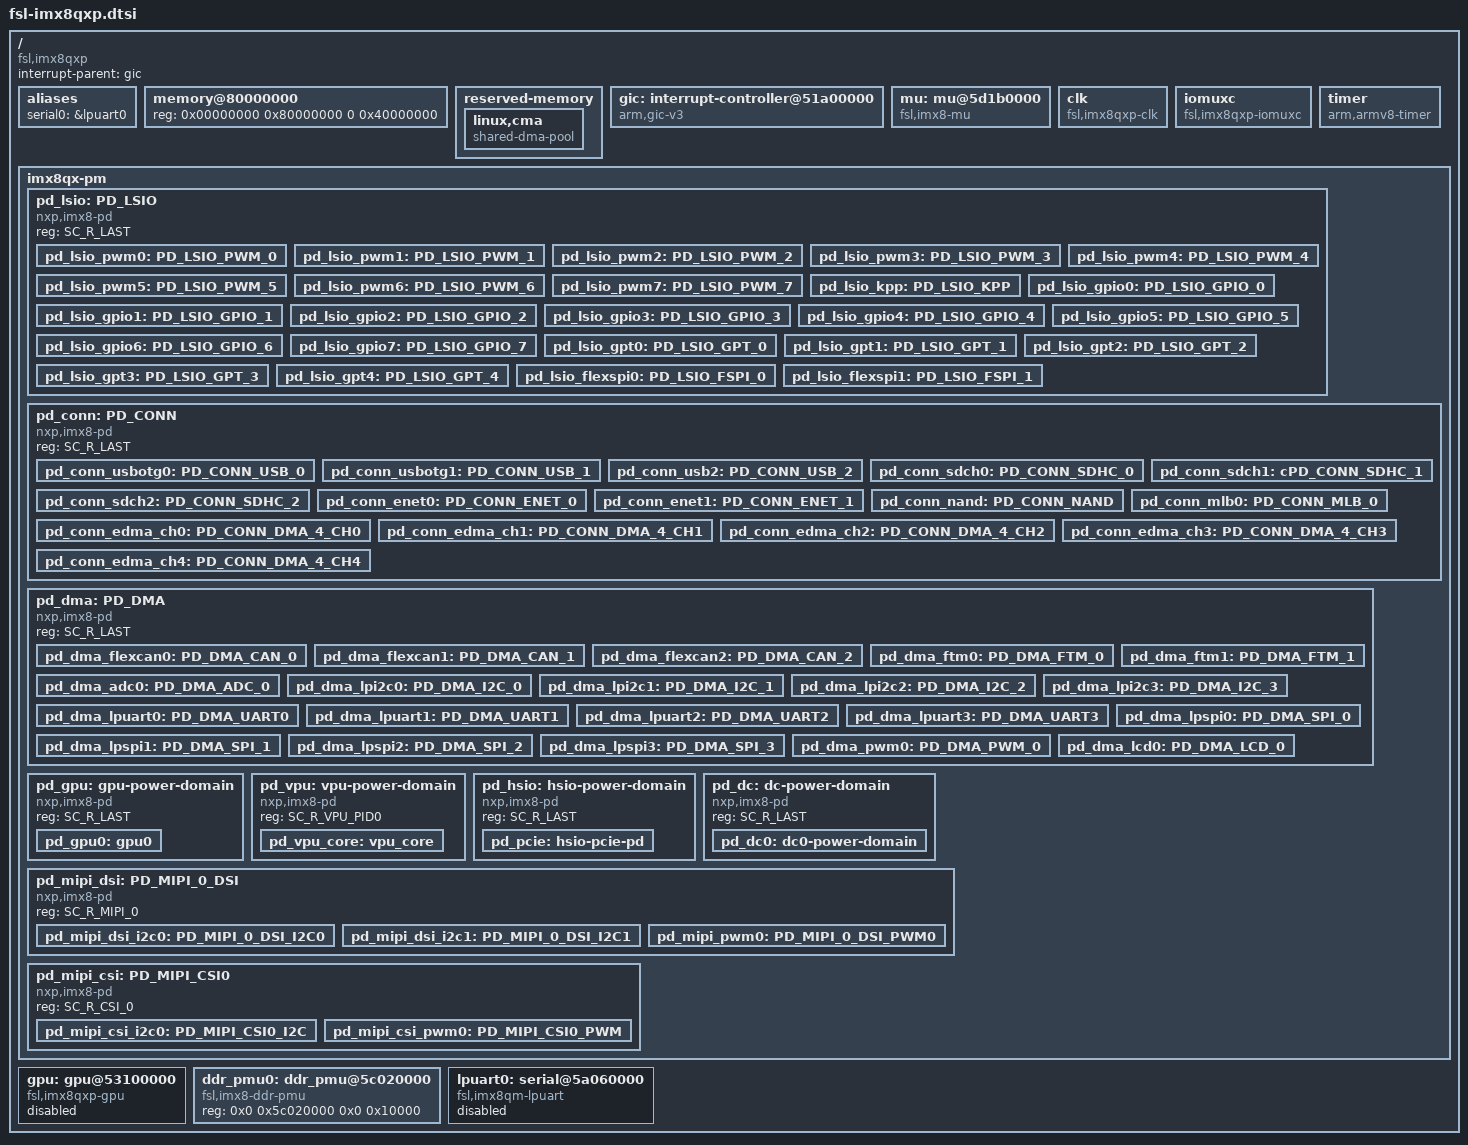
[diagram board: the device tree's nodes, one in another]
/*
 * Copyright (C) 2016 Freescale Semiconductor, Inc.
 * Copyright 2017 NXP
 *
 * This program is free software; you can redistribute it and/or
 * modify it under the terms of the GNU General Public License
 * as published by the Free Software Foundation; either version 2
 * of the License, or (at your option) any later version.
 *
 * This program is distributed in the hope that it will be useful,
 * but WITHOUT ANY WARRANTY; without even the implied warranty of
 * MERCHANTABILITY or FITNESS FOR A PARTICULAR PURPOSE.  See the
 * GNU General Public License for more details.
 */

#include <dt-bindings/interrupt-controller/arm-gic.h>
#include "fsl-imx8-ca35.dtsi"
#include <dt-bindings/soc/imx_rsrc.h>
#include <dt-bindings/soc/imx8_pd.h>
#include <dt-bindings/clock/imx8qxp-clock.h>
#include <dt-bindings/pinctrl/pads-imx8qxp.h>

/ {
	compatible = "fsl,imx8qxp";
	interrupt-parent = <&gic>;
	#address-cells = <2>;
	#size-cells = <2>;

	aliases {
		serial0 = &lpuart0;
	};

	memory@80000000 {
		device_type = "memory";
		reg = <0x00000000 0x80000000 0 0x40000000>;
		      /* DRAM space - 1, size : 1 GB DRAM */
	};

	reserved-memory {
		#address-cells = <2>;
		#size-cells = <2>;
		ranges;

		/* global autoconfigured region for contiguous allocations */
		linux,cma {
			compatible = "shared-dma-pool";
			reusable;
			size = <0 0x08000000>;
			alloc-ranges = <0 0x80000000 0 0x80000000>;
			linux,cma-default;
		};
	};

	gic: interrupt-controller@51a00000 {
		compatible = "arm,gic-v3";
		reg = <0x0 0x51a00000 0 0x10000>, /* GIC Dist */
		      <0x0 0x51b00000 0 0xC0000>; /* GICR (RD_base + SGI_base) */
		#interrupt-cells = <3>;
		interrupt-controller;
		interrupts = <GIC_PPI 9
			(GIC_CPU_MASK_SIMPLE(6) | IRQ_TYPE_LEVEL_HIGH)>;
	};

	mu: mu@5d1b0000 {
		compatible = "fsl,imx8-mu";
		reg = <0x0 0x5d1b0000 0x0 0x10000>;
		interrupts = <GIC_SPI 176 IRQ_TYPE_LEVEL_HIGH>;
		fsl,scu_ap_mu_id = <0>;
		status = "okay";
	};

	clk: clk {
		compatible = "fsl,imx8qxp-clk";
		#clock-cells = <1>;
	};

	iomuxc: iomuxc {
		compatible = "fsl,imx8qxp-iomuxc";
	};

	timer {
		compatible = "arm,armv8-timer";
		interrupts = <GIC_PPI 13 (GIC_CPU_MASK_SIMPLE(6) | IRQ_TYPE_LEVEL_LOW)>, /* Physical Secure */
			     <GIC_PPI 14 (GIC_CPU_MASK_SIMPLE(6) | IRQ_TYPE_LEVEL_LOW)>, /* Physical Non-Secure */
			     <GIC_PPI 11 (GIC_CPU_MASK_SIMPLE(6) | IRQ_TYPE_LEVEL_LOW)>, /* Virtual */
			     <GIC_PPI 10 (GIC_CPU_MASK_SIMPLE(6) | IRQ_TYPE_LEVEL_LOW)>; /* Hypervisor */
		clock-frequency = <8000000>;
	};

	imx8qx-pm {
		#address-cells = <1>;
		#size-cells = <0>;

		pd_lsio: PD_LSIO {
			compatible = "nxp,imx8-pd";
			reg = <SC_R_LAST>;
			#power-domain-cells = <0>;
			#address-cells = <1>;
			#size-cells = <0>;

			pd_lsio_pwm0: PD_LSIO_PWM_0 {
				reg = <SC_R_PWM_0>;
				#power-domain-cells = <0>;
				power-domains = <&pd_lsio>;
			};
			pd_lsio_pwm1: PD_LSIO_PWM_1 {
				reg = <SC_R_PWM_1>;
				#power-domain-cells = <0>;
				power-domains = <&pd_lsio>;
			};
			pd_lsio_pwm2: PD_LSIO_PWM_2 {
				reg = <SC_R_PWM_2>;
				#power-domain-cells = <0>;
				power-domains = <&pd_lsio>;
			};
			pd_lsio_pwm3: PD_LSIO_PWM_3 {
				reg = <SC_R_PWM_3>;
				#power-domain-cells = <0>;
				power-domains = <&pd_lsio>;
			};
			pd_lsio_pwm4: PD_LSIO_PWM_4 {
				reg = <SC_R_PWM_4>;
				#power-domain-cells = <0>;
				power-domains = <&pd_lsio>;
			};
			pd_lsio_pwm5: PD_LSIO_PWM_5 {
				reg = <SC_R_PWM_5>;
				#power-domain-cells = <0>;
				power-domains = <&pd_lsio>;
			};
			pd_lsio_pwm6: PD_LSIO_PWM_6 {
				reg = <SC_R_PWM_6>;
				#power-domain-cells = <0>;
				power-domains = <&pd_lsio>;
			};
			pd_lsio_pwm7: PD_LSIO_PWM_7 {
				reg = <SC_R_PWM_7>;
				#power-domain-cells = <0>;
				power-domains = <&pd_lsio>;
			};
			pd_lsio_kpp: PD_LSIO_KPP {
				reg = <SC_R_KPP>;
				#power-domain-cells = <0>;
				power-domains = <&pd_lsio>;
			};
			pd_lsio_gpio0: PD_LSIO_GPIO_0 {
				reg = <SC_R_GPIO_0>;
				#power-domain-cells = <0>;
				power-domains = <&pd_lsio>;
			};
			pd_lsio_gpio1: PD_LSIO_GPIO_1 {
				reg = <SC_R_GPIO_1>;
				#power-domain-cells = <0>;
				power-domains = <&pd_lsio>;
			};
			pd_lsio_gpio2: PD_LSIO_GPIO_2 {
				reg = <SC_R_GPIO_2>;
				#power-domain-cells = <0>;
				power-domains = <&pd_lsio>;
			};
			pd_lsio_gpio3: PD_LSIO_GPIO_3 {
				reg = <SC_R_GPIO_3>;
				#power-domain-cells = <0>;
				power-domains = <&pd_lsio>;
			};
			pd_lsio_gpio4: PD_LSIO_GPIO_4 {
				reg = <SC_R_GPIO_4>;
				#power-domain-cells = <0>;
				power-domains = <&pd_lsio>;
			};
			pd_lsio_gpio5: PD_LSIO_GPIO_5{
				reg = <SC_R_GPIO_5>;
				#power-domain-cells = <0>;
				power-domains = <&pd_lsio>;
			};
			pd_lsio_gpio6:PD_LSIO_GPIO_6 {
				reg = <SC_R_GPIO_6>;
				#power-domain-cells = <0>;
				power-domains = <&pd_lsio>;
			};
			pd_lsio_gpio7: PD_LSIO_GPIO_7 {
				reg = <SC_R_GPIO_7>;
				#power-domain-cells = <0>;
				power-domains = <&pd_lsio>;
			};
			pd_lsio_gpt0: PD_LSIO_GPT_0 {
				reg = <SC_R_GPT_0>;
				#power-domain-cells = <0>;
				power-domains = <&pd_lsio>;
			};
			pd_lsio_gpt1: PD_LSIO_GPT_1 {
				reg = <SC_R_GPT_1>;
				#power-domain-cells = <0>;
				power-domains = <&pd_lsio>;
			};
			pd_lsio_gpt2: PD_LSIO_GPT_2 {
				reg = <SC_R_GPT_2>;
				#power-domain-cells = <0>;
				power-domains = <&pd_lsio>;
			};
			pd_lsio_gpt3: PD_LSIO_GPT_3 {
				reg = <SC_R_GPT_3>;
				#power-domain-cells = <0>;
				power-domains = <&pd_lsio>;
			};
			pd_lsio_gpt4: PD_LSIO_GPT_4 {
				reg = <SC_R_GPT_4>;
				#power-domain-cells = <0>;
				power-domains = <&pd_lsio>;
			};
			pd_lsio_flexspi0: PD_LSIO_FSPI_0 {
				reg = <SC_R_FSPI_0>;
				#power-domain-cells = <0>;
				power-domains = <&pd_lsio>;
			};
			pd_lsio_flexspi1: PD_LSIO_FSPI_1{
				reg = <SC_R_FSPI_1>;
				#power-domain-cells = <0>;
				power-domains = <&pd_lsio>;
			};
		};

		pd_conn: PD_CONN {
			compatible = "nxp,imx8-pd";
			reg = <SC_R_LAST>;
			#power-domain-cells = <0>;
			#address-cells = <1>;
			#size-cells = <0>;

			pd_conn_usbotg0: PD_CONN_USB_0 {
				reg = <SC_R_USB_0>;
				#power-domain-cells = <0>;
				power-domains = <&pd_conn>;
			};
			pd_conn_usbotg1: PD_CONN_USB_1 {
				reg = <SC_R_USB_1>;
				#power-domain-cells = <0>;
				power-domains = <&pd_conn>;
			};
			pd_conn_usb2: PD_CONN_USB_2 {
				reg = <SC_R_USB_2>;
				#power-domain-cells = <0>;
				power-domains = <&pd_conn>;
			};
			pd_conn_sdch0: PD_CONN_SDHC_0 {
				reg = <SC_R_SDHC_0>;
				#power-domain-cells = <0>;
				power-domains = <&pd_conn>;
			};
			pd_conn_sdch1: cPD_CONN_SDHC_1 {
				reg = <SC_R_SDHC_1>;
				#power-domain-cells = <0>;
				power-domains = <&pd_conn>;
			};
			pd_conn_sdch2: PD_CONN_SDHC_2 {
				reg = <SC_R_SDHC_2>;
				#power-domain-cells = <0>;
				power-domains = <&pd_conn>;
			};
			pd_conn_enet0: PD_CONN_ENET_0 {
				reg = <SC_R_ENET_0>;
				#power-domain-cells = <0>;
				power-domains = <&pd_conn>;
			};
			pd_conn_enet1: PD_CONN_ENET_1 {
				reg = <SC_R_ENET_1>;
				#power-domain-cells = <0>;
				power-domains = <&pd_conn>;
			};
			pd_conn_nand: PD_CONN_NAND {
				reg = <SC_R_NAND>;
				#power-domain-cells = <0>;
				power-domains = <&pd_conn>;
			};
			pd_conn_mlb0: PD_CONN_MLB_0 {
				reg = <SC_R_MLB_0>;
				#power-domain-cells = <0>;
				power-domains = <&pd_conn>;
			};
			pd_conn_edma_ch0: PD_CONN_DMA_4_CH0 {
				reg = <SC_R_DMA_4_CH0>;
				#power-domain-cells = <0>;
				power-domains =<&pd_conn>;
			};
			pd_conn_edma_ch1: PD_CONN_DMA_4_CH1 {
				reg = <SC_R_DMA_4_CH1>;
				#power-domain-cells = <0>;
				power-domains =<&pd_conn>;
			};
			pd_conn_edma_ch2: PD_CONN_DMA_4_CH2 {
				reg = <SC_R_DMA_4_CH2>;
				#power-domain-cells = <0>;
				power-domains =<&pd_conn>;
			};
			pd_conn_edma_ch3: PD_CONN_DMA_4_CH3 {
				reg = <SC_R_DMA_4_CH3>;
				#power-domain-cells = <0>;
				power-domains =<&pd_conn>;
			};
			pd_conn_edma_ch4: PD_CONN_DMA_4_CH4 {
				reg = <SC_R_DMA_4_CH4>;
				#power-domain-cells = <0>;
				power-domains =<&pd_conn>;
			};
		};

		pd_dma: PD_DMA {
			compatible = "nxp,imx8-pd";
			reg = <SC_R_LAST>;
			#power-domain-cells = <0>;
			#address-cells = <1>;
			#size-cells = <0>;

			pd_dma_flexcan0: PD_DMA_CAN_0 {
				reg = <SC_R_CAN_0>;
				#power-domain-cells = <0>;
				power-domains = <&pd_dma>;
			};
			pd_dma_flexcan1: PD_DMA_CAN_1 {
				reg = <SC_R_CAN_1>;
				#power-domain-cells = <0>;
				power-domains = <&pd_dma>;
			};
			pd_dma_flexcan2: PD_DMA_CAN_2 {
				reg = <SC_R_CAN_2>;
				#power-domain-cells = <0>;
				power-domains = <&pd_dma>;
			};
			pd_dma_ftm0: PD_DMA_FTM_0 {
				reg = <SC_R_FTM_0>;
				#power-domain-cells = <0>;
				power-domains = <&pd_dma>;
			};
			pd_dma_ftm1: PD_DMA_FTM_1 {
				reg = <SC_R_FTM_1>;
				#power-domain-cells = <0>;
				power-domains = <&pd_dma>;
			};
			pd_dma_adc0: PD_DMA_ADC_0 {
				reg = <SC_R_ADC_0>;
				#power-domain-cells = <0>;
				power-domains = <&pd_dma>;
			};
			pd_dma_lpi2c0: PD_DMA_I2C_0 {
				reg = <SC_R_I2C_0>;
				#power-domain-cells = <0>;
				power-domains = <&pd_dma>;
			};
			pd_dma_lpi2c1: PD_DMA_I2C_1 {
				reg = <SC_R_I2C_1>;
				#power-domain-cells = <0>;
				power-domains = <&pd_dma>;
			};
			pd_dma_lpi2c2:PD_DMA_I2C_2 {
				reg = <SC_R_I2C_2>;
				#power-domain-cells = <0>;
				power-domains = <&pd_dma>;
			};
			pd_dma_lpi2c3: PD_DMA_I2C_3 {
				reg = <SC_R_I2C_3>;
				#power-domain-cells = <0>;
				power-domains = <&pd_dma>;
			};
			pd_dma_lpuart0: PD_DMA_UART0 {
				reg = <SC_R_UART_0>;
				#power-domain-cells = <0>;
				power-domains = <&pd_dma>;
			};
			pd_dma_lpuart1: PD_DMA_UART1 {
				reg = <SC_R_UART_1>;
				#power-domain-cells = <0>;
				power-domains = <&pd_dma>;
			};
			pd_dma_lpuart2: PD_DMA_UART2 {
				reg = <SC_R_UART_2>;
				#power-domain-cells = <0>;
				power-domains = <&pd_dma>;
			};
			pd_dma_lpuart3: PD_DMA_UART3 {
				reg = <SC_R_UART_3>;
				#power-domain-cells = <0>;
				power-domains = <&pd_dma>;
			};
			pd_dma_lpspi0: PD_DMA_SPI_0 {
				reg = <SC_R_SPI_0>;
				#power-domain-cells = <0>;
				power-domains = <&pd_dma>;
			};
			pd_dma_lpspi1: PD_DMA_SPI_1 {
				reg = <SC_R_SPI_1>;
				#power-domain-cells = <0>;
				power-domains = <&pd_dma>;
			};
			pd_dma_lpspi2: PD_DMA_SPI_2 {
				reg = <SC_R_SPI_2>;
				#power-domain-cells = <0>;
				power-domains = <&pd_dma>;
			};
			pd_dma_lpspi3: PD_DMA_SPI_3 {
				reg = <SC_R_SPI_3>;
				#power-domain-cells = <0>;
				power-domains = <&pd_dma>;
			};
			pd_dma_pwm0: PD_DMA_PWM_0 {
				reg = <SC_R_LCD_0_PWM_0>;
				#power-domain-cells = <0>;
				power-domains = <&pd_dma>;
			};
			pd_dma_lcd0: PD_DMA_LCD_0 {
				reg = <SC_R_LCD_0>;
				#power-domain-cells = <0>;
				power-domains = <&pd_dma>;
			};
		};

		pd_gpu: gpu-power-domain {
			compatible = "nxp,imx8-pd";
			reg = <SC_R_LAST>;
			#power-domain-cells = <0>;
			#address-cells = <1>;
			#size-cells = <0>;

			pd_gpu0: gpu0 {
				name = "gpu0";
				reg = <SC_R_GPU_0_PID0>;
				#power-domain-cells = <0>;
				power-domains =<&pd_gpu>;
				#address-cells = <1>;
				#size-cells = <0>;
			};
		};

		pd_vpu: vpu-power-domain {
			compatible = "nxp,imx8-pd";
			reg = <SC_R_VPU_PID0>;
			#power-domain-cells = <0>;
			#address-cells = <1>;
			#size-cells = <0>;

			pd_vpu_core: vpu_core {
				name = "vpu_core";
				reg = <SC_R_VPUCORE>;
				#power-domain-cells = <0>;
				power-domains =<&pd_vpu>;
			};
		};

		pd_hsio: hsio-power-domain {
			compatible = "nxp,imx8-pd";
			reg = <SC_R_LAST>;
			#power-domain-cells = <0>;
			#address-cells = <1>;
			#size-cells = <0>;

			pd_pcie: hsio-pcie-pd {
				name = "hsio-pcie-pd";
				reg = <SC_R_PCIE_A>;
				#power-domain-cells = <0>;
				power-domains =<&pd_hsio>;
			};
		};

		pd_dc: dc-power-domain {
			compatible = "nxp,imx8-pd";
			reg = <SC_R_LAST>;
			#power-domain-cells = <0>;
			#address-cells = <1>;
			#size-cells = <0>;

			pd_dc0: dc0-power-domain {
				name = "dc0-power-domain";
				reg = <SC_R_DC_0>;
				#power-domain-cells = <0>;
				power-domains =<&pd_dc>;
			};
		};

		pd_mipi_dsi: PD_MIPI_0_DSI {
			compatible = "nxp,imx8-pd";
			reg = <SC_R_MIPI_0>;
			#power-domain-cells = <0>;
			#address-cells = <1>;
			#size-cells = <0>;

			pd_mipi_dsi_i2c0: PD_MIPI_0_DSI_I2C0 {
				name = "mipi0_dsi_i2c0";
				reg = <SC_R_MIPI_0_I2C_0>;
				power-domains =<&pd_mipi_dsi>;
			};
			pd_mipi_dsi_i2c1: PD_MIPI_0_DSI_I2C1 {
				name = "mipi0_dsi_i2c1";
				reg = <SC_R_MIPI_0_I2C_1>;
				power-domains =<&pd_mipi_dsi>;
			};
			pd_mipi_pwm0: PD_MIPI_0_DSI_PWM0 {
				name = "mipi0_dsi_pwm0";
				reg = <SC_R_MIPI_0_PWM_0>;
				power-domains =<&pd_mipi_dsi>;
			};
		};

		pd_mipi_csi: PD_MIPI_CSI0 {
			compatible = "nxp,imx8-pd";
			reg = <SC_R_CSI_0>;
			#power-domain-cells = <0>;
			#address-cells = <1>;
			#size-cells = <0>;

			pd_mipi_csi_i2c0: PD_MIPI_CSI0_I2C {
				name = "mipi_csi0_i2c";
				reg = <SC_R_CSI_0_I2C_0>;
				power-domains =<&pd_mipi_csi>;
			};
			pd_mipi_csi_pwm0: PD_MIPI_CSI0_PWM {
				name = "mipi_csi0_pwm";
				reg = <SC_R_CSI_0_PWM_0>;
				power-domains =<&pd_mipi_dsi>;
			};
		};
	};

	gpu: gpu@53100000 {
		compatible = "fsl,imx8qxp-gpu", "fsl,imx8x-gpu";
		reg = <0x0 0x53100000 0 0x40000>,
			<0x0 0x80000000 0x0 0x08000000>,
			<0x0 0x0 0x0 0x2000000>;
		reg-names = "iobase_3d_0", "phys_baseaddr",
			"contiguous_mem";
		interrupts = <0 64 0x4>;
		interrupt-names = "irq_3d_0";
		clocks = <&clk IMX8QXP_GPU0_CORE_CLK>,
			<&clk IMX8QXP_GPU0_SHADER_CLK>;
		clock-names = "clk_core_3d_0", "clk_shader_3d_0";
		assigned-clocks = <&clk IMX8QXP_GPU0_CORE_CLK>,
			<&clk IMX8QXP_GPU0_SHADER_CLK>;
		assigned-clock-rates = <650000000>, <700000000>;
		status = "disabled";
	};

	ddr_pmu0: ddr_pmu@5c020000 {
		compatible = "fsl,imx8-ddr-pmu";
		reg = <0x0 0x5c020000 0x0 0x10000>;
	};

	lpuart0: serial@5a060000 {
		compatible = "fsl,imx8qm-lpuart";
		reg = <0x0 0x5a060000 0x0 0x1000>;
		interrupts = <GIC_SPI 225 IRQ_TYPE_LEVEL_HIGH>;
		interrupt-parent = <&gic>;
		clocks = <&clk IMX8QXP_UART0_CLK>;
		clock-names = "ipg";
		status = "disabled";
	};
};
